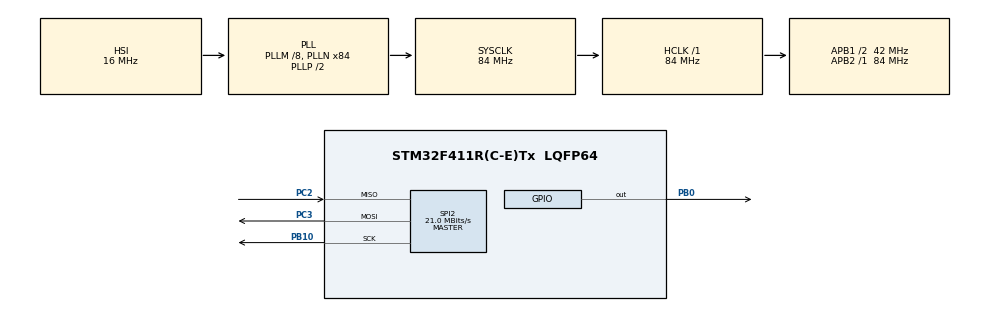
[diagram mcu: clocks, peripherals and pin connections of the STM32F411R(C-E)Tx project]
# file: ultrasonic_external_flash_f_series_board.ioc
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Mcu.Family=STM32F4
Mcu.Name=STM32F411R(C-E)Tx
Mcu.Package=LQFP64
NVIC.PriorityGroup=NVIC_PRIORITYGROUP_4
PB0.PinState=GPIO_PIN_SET
PB0.Signal=GPIO_Output
PB10.Mode=Full_Duplex_Master
PB10.Signal=SPI2_SCK
PC2.Mode=Full_Duplex_Master
PC2.Signal=SPI2_MISO
PC3.Mode=Full_Duplex_Master
PC3.Signal=SPI2_MOSI
ProjectManager.HeapSize=0x200
ProjectManager.StackSize=0x400
ProjectManager.TargetToolchain=STM32CubeIDE
RCC.48MHZClocksFreq_Value=42000000
RCC.AHBFreq_Value=84000000
RCC.APB1CLKDivider=RCC_HCLK_DIV2
RCC.APB1Freq_Value=42000000
RCC.APB1TimFreq_Value=84000000
RCC.APB2Freq_Value=84000000
RCC.APB2TimFreq_Value=84000000
RCC.CortexFreq_Value=84000000
RCC.HCLKFreq_Value=84000000
RCC.HSE_VALUE=25000000
RCC.HSI_VALUE=16000000
RCC.LSE_VALUE=32768
RCC.PLLM=8
RCC.PLLN=84
RCC.SYSCLKFreq_VALUE=84000000
RCC.SYSCLKSource=RCC_SYSCLKSOURCE_PLLCLK
RCC.VCOOutputFreq_Value=168000000
SPI2.CalculateBaudRate=21.0 MBits/s
SPI2.Direction=SPI_DIRECTION_2LINES
SPI2.Mode=SPI_MODE_MASTER
SPI2.VirtualType=VM_MASTER
board=custom

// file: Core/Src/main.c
/* USER CODE BEGIN Header */
/**
  ******************************************************************************
  * @file           : main.c
  * @brief          : Main program body
  ******************************************************************************
  * @attention
  *
  * Copyright (c) 2025 STMicroelectronics.
  * All rights reserved.
  *
  * This software is licensed under terms that can be found in the LICENSE file
  * in the root directory of this software component.
  * If no LICENSE file comes with this software, it is provided AS-IS.
  *
  ******************************************************************************
  */
/* USER CODE END Header */
#include "main.h"
#include "spi.h"
#include "gpio.h"

/* USER CODE BEGIN Includes */
#include "w25qxx.h"

/* USER CODE END Includes */

void SystemClock_Config(void);

int main(void)
{

  /* USER CODE BEGIN 1 */
	uint8_t ucDataBuff[] = "Hello Flash Iam From STM32";
	uint16_t uhTxSize = sizeof(ucDataBuff);
	uint8_t ucRxBuff[100] = {0};

  /* USER CODE END 1 */

  /* MCU Configuration--------------------------------------------------------*/

  /* Reset of all peripherals, Initializes the Flash interface and the Systick. */
  HAL_Init();

  /* Configure the system clock */
  SystemClock_Config();

  /* Initialize all configured peripherals */
  MX_GPIO_Init();
  MX_SPI2_Init();

  /* Infinite loop */
  /* USER CODE BEGIN WHILE */

  W25QxxFlashWriteData(ucDataBuff, uhTxSize, USER_ADDR_1);
  while (1)
  {
    /* USER CODE END WHILE */

    /* USER CODE BEGIN 3 */

	  W25QxxFlashReadData(ucRxBuff, uhTxSize, USER_ADDR_1);

	  HAL_Delay(100);
  }
  /* USER CODE END 3 */
}

void SystemClock_Config(void)
{
  RCC_OscInitTypeDef RCC_OscInitStruct = {0};
  RCC_ClkInitTypeDef RCC_ClkInitStruct = {0};

  /** Configure the main internal regulator output voltage
  */
  __HAL_RCC_PWR_CLK_ENABLE();
  __HAL_PWR_VOLTAGESCALING_CONFIG(PWR_REGULATOR_VOLTAGE_SCALE1);

  /** Initializes the RCC Oscillators according to the specified parameters
  * in the RCC_OscInitTypeDef structure.
  */
  RCC_OscInitStruct.OscillatorType = RCC_OSCILLATORTYPE_HSI;
  RCC_OscInitStruct.HSIState = RCC_HSI_ON;
  RCC_OscInitStruct.HSICalibrationValue = RCC_HSICALIBRATION_DEFAULT;
  RCC_OscInitStruct.PLL.PLLState = RCC_PLL_ON;
  RCC_OscInitStruct.PLL.PLLSource = RCC_PLLSOURCE_HSI;
  RCC_OscInitStruct.PLL.PLLM = 8;
  RCC_OscInitStruct.PLL.PLLN = 84;
  RCC_OscInitStruct.PLL.PLLP = RCC_PLLP_DIV2;
  RCC_OscInitStruct.PLL.PLLQ = 4;
  if (HAL_RCC_OscConfig(&RCC_OscInitStruct) != HAL_OK)
  {
    Error_Handler();
  }

  /** Initializes the CPU, AHB and APB buses clocks
  */
  RCC_ClkInitStruct.ClockType = RCC_CLOCKTYPE_HCLK|RCC_CLOCKTYPE_SYSCLK
                              |RCC_CLOCKTYPE_PCLK1|RCC_CLOCKTYPE_PCLK2;
  RCC_ClkInitStruct.SYSCLKSource = RCC_SYSCLKSOURCE_PLLCLK;
  RCC_ClkInitStruct.AHBCLKDivider = RCC_SYSCLK_DIV1;
  RCC_ClkInitStruct.APB1CLKDivider = RCC_HCLK_DIV2;
  RCC_ClkInitStruct.APB2CLKDivider = RCC_HCLK_DIV1;

  if (HAL_RCC_ClockConfig(&RCC_ClkInitStruct, FLASH_LATENCY_2) != HAL_OK)
  {
    Error_Handler();
  }
}

void Error_Handler(void)
{
  __disable_irq();
  while (1)
  {
  }
}
